VERSION ""

NS_ :

BS_:

BU_: XXX EPS DSU

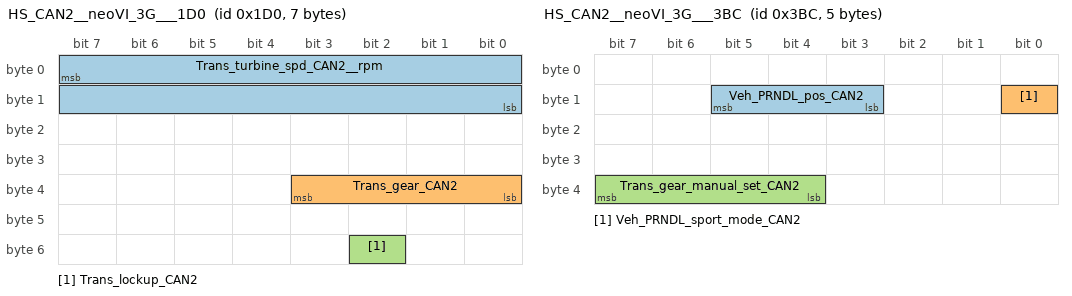
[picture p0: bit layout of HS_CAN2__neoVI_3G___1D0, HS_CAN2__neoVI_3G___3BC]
BO_ 464 HS_CAN2__neoVI_3G___1D0: 7 Vector__XXX
 SG_ Trans_turbine_spd_CAN2__rpm : 7|16@0+ (0.39045,0) [32|25426.8125] "rpm" Vector__XXX
 SG_ Trans_gear_CAN2 : 35|4@0+ (1,1) [0|15] "" Vector__XXX
 SG_ Trans_lockup_CAN2 : 50|1@0+ (1,0) [0|0] "" Vector__XXX

BO_ 452 HS_CAN2__neoVI_3G___1C4: 8 Vector__XXX
 SG_ Eng_spd_CAN2__rpm : 7|16@0+ (0.78125,0) [0|51199.21875] "rpm" Vector__XXX
 SG_ Signal_1 : 55|16@0+ (1,0) [0|65535] "" Vector__XXX

BO_ 865 HS_CAN2__neoVI_3G___361: 3 Vector__XXX
 SG_ Pedal_accel_pos_CAN2__per : 23|8@0+ (0.5,0) [0|127.5] "per" Vector__XXX

BO_ 956 HS_CAN2__neoVI_3G___3BC: 5 Vector__XXX
 SG_ Veh_PRNDL_pos_CAN2 : 13|3@0+ (1,0) [0|7] "" Vector__XXX
 SG_ Veh_PRNDL_sport_mode_CAN2 : 8|1@0+ (1,0) [0|0] "" Vector__XXX
 SG_ Trans_gear_manual_set_CAN2 : 39|4@0+ (1,0) [0|15] "" Vector__XXX
